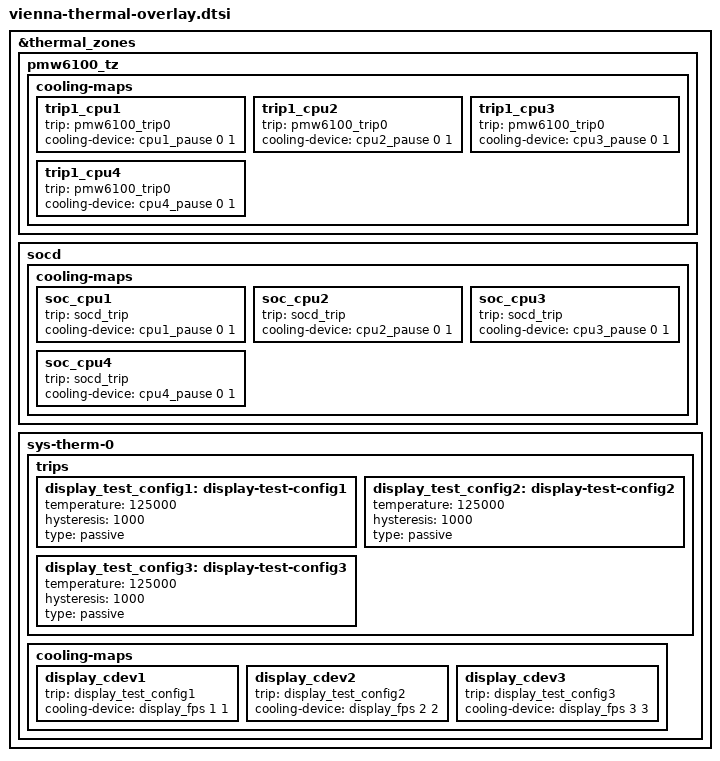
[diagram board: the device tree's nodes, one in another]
// SPDX-License-Identifier: BSD-3-Clause
/*
 * Copyright (c) Qualcomm Technologies, Inc. and/or its subsidiaries.
 */

#include <dt-bindings/thermal/thermal_qti.h>

&thermal_zones {
	pmw6100_tz {
		cooling-maps {
			trip1_cpu1 {
				trip = <&pmw6100_trip0>;
				cooling-device = <&cpu1_pause 0 1>;
			};

			trip1_cpu2 {
				trip = <&pmw6100_trip0>;
				cooling-device = <&cpu2_pause 0 1>;
			};

			trip1_cpu3 {
				trip = <&pmw6100_trip0>;
				cooling-device = <&cpu3_pause 0 1>;
			};

			trip1_cpu4 {
				trip = <&pmw6100_trip0>;
				cooling-device = <&cpu4_pause 0 1>;
			};
		};
	};

	socd {
		cooling-maps {
			soc_cpu1 {
				trip = <&socd_trip>;
				cooling-device = <&cpu1_pause 0 1>;
			};

			soc_cpu2 {
				trip = <&socd_trip>;
				cooling-device = <&cpu2_pause 0 1>;
			};

			soc_cpu3 {
				trip = <&socd_trip>;
				cooling-device = <&cpu3_pause 0 1>;
			};

			soc_cpu4 {
				trip = <&socd_trip>;
				cooling-device = <&cpu4_pause 0 1>;
			};
		};
	};

	sys-therm-0 {
		trips {
			display_test_config1: display-test-config1 {
				temperature = <125000>;
				hysteresis = <1000>;
				type = "passive";
			};

			display_test_config2: display-test-config2 {
				temperature = <125000>;
				hysteresis = <1000>;
				type = "passive";
			};

			display_test_config3: display-test-config3 {
				temperature = <125000>;
				hysteresis = <1000>;
				type = "passive";
			};
		};

		cooling-maps {
			display_cdev1 {
				trip = <&display_test_config1>;
				cooling-device = <&display_fps 1 1>;
			};

			display_cdev2 {
				trip = <&display_test_config2>;
				cooling-device = <&display_fps 2 2>;
			};

			display_cdev3 {
				trip = <&display_test_config3>;
				cooling-device = <&display_fps 3 3>;
			};
		};
	};
};

